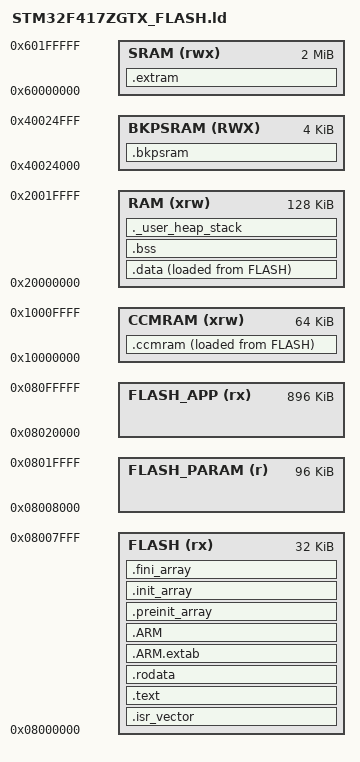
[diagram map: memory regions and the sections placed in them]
/*
******************************************************************************
**
** @file        : LinkerScript.ld
**
** @author      : Auto-generated by STM32CubeIDE
**
** @brief       : Linker script for STM32F417ZGTx Device from STM32F4 series
**                      1024KBytes FLASH
**                      64KBytes CCMRAM
**                      128KBytes RAM
**
**                Set heap size, stack size and stack location according
**                to application requirements.
**
**                Set memory bank area and size if external memory is used
**
**  Target      : STMicroelectronics STM32
**
**  Distribution: The file is distributed as is, without any warranty
**                of any kind.
**
******************************************************************************
** @attention
**
** Copyright (c) 2026 STMicroelectronics.
** All rights reserved.
**
** This software is licensed under terms that can be found in the LICENSE file
** in the root directory of this software component.
** If no LICENSE file comes with this software, it is provided AS-IS.
**
******************************************************************************
*/

/*
===================================================================================
                       STM32F4 CUSTOM MEMORY MAP ARCHITECTURE
===================================================================================
 [REGION]         [ADDRESS RANGE]         [SIZE]     [PURPOSE / TARGET ASSIGNMENT]
 ----------------------------------------------------------------------------------
 INTERNAL FLASH:
  Sector 0        0x0800 0000 - 0x0800 3FFF   16 KB    DFU Bootloader Vector/Init
  Sector 1        0x0800 4000 - 0x0800 7FFF   16 KB    DFU Bootloader Main Code (32KB)
  Sector 2        0x0800 8000 - 0x0800 BFFF   16 KB    Configuration Parameters A
  Sector 3        0x0800 C000 - 0x0800 FFFF   16 KB    Configuration Parameters B
  Sector 4        0x0801 0000 - 0x0801 FFFF   64 KB    Configuration Parameters C (96KB)
  Sectors 5-11    0x0802 0000 - 0x080F FFFF  896 KB    User Application Space (20KB+)

 EXTERNAL SYSTEM BUS:
  FSMC Bank 1     0x6000 0000 - 0x601F FFFF  2048 KB   External Parallel SRAM (2 MB)

===================================================================================
                       CRITICAL CONFIGURATION ATTENTION REMARKS
===================================================================================
 1. HARDWARE PROTECTION RULES (usbd_dfu_if.c):
    - Any incoming USB write/erase target address < 0x08020000 MUST be aborted 
      with USBD_FAIL to preserve the Bootloader (Sectors 0-1) and Parameters (Sectors 2-4).
    - Address targets between 0x60000000 and 0x601FFFFF must bypass standard internal
      flash procedures and route directly onto the parallel FSMC lines byte-by-byte.

 2. USER APPLICATION SETTINGS (Application Project Compiler Hooks):
    - Application Linker Script must set: FLASH (rx) ORIGIN = 0x08020000
    - Vector Table Offset (system_stm32f4xx.c) must read: VECT_TAB_OFFSET = 0x00020000U

 3. RUNTIME MEMORY MAPPING RULES:
    - External SRAM variables must utilize the (NOLOAD) linker section attribute to
      prevent the startup code from clearing it before MX_FSMC_Init() fires.
===================================================================================
*/

/* Entry Point */
ENTRY(Reset_Handler)

/* Highest address of the user mode stack */
_estack = ORIGIN(RAM) + LENGTH(RAM); /* end of "RAM" Ram type memory */

_Min_Heap_Size = 0x200; /* required amount of heap */
_Min_Stack_Size = 0x400; /* required amount of stack */

/* Memories definition */
MEMORY
{
  CCMRAM    (xrw)    : ORIGIN = 0x10000000,   LENGTH = 64K
  RAM    (xrw)    : ORIGIN = 0x20000000,   LENGTH = 128K
  BKPSRAM (RWX) : ORIGIN = 0x40024000, LENGTH = 4K
  SRAM (rwx)    : ORIGIN = 0x60000000, LENGTH =   2048k
  
  /* Primary active code execution space (Sectors 0-1) */
  FLASH    (rx)    : ORIGIN = 0x8000000,   LENGTH = 32K
  /* Parameter retention sector assignments (Sectors 2-4) */
  FLASH_PARAM  (r)   : ORIGIN = 0x08008000, LENGTH = 96K
  /* Main target runtime deployment space (Sectors 5-11) */
  FLASH_APP    (rx)  : ORIGIN = 0x08020000, LENGTH = 896K
}

/* Sections */
SECTIONS
{

  /* The startup code into "FLASH" Rom type memory */
  .isr_vector :
  {
    . = ALIGN(4);
    KEEP(*(.isr_vector)) /* Startup code */
    . = ALIGN(4);
  } >FLASH

  /* The program code and other data into "FLASH" Rom type memory */
  .text :
  {
    . = ALIGN(4);
    *(.text)           /* .text sections (code) */
    *(.text*)          /* .text* sections (code) */
    *(.glue_7)         /* glue arm to thumb code */
    *(.glue_7t)        /* glue thumb to arm code */
    *(.eh_frame)

    KEEP (*(.init))
    KEEP (*(.fini))

    . = ALIGN(4);
    _etext = .;        /* define a global symbols at end of code */
  } >FLASH

  /* Constant data into "FLASH" Rom type memory */
  .rodata :
  {
    . = ALIGN(4);
    *(.rodata)         /* .rodata sections (constants, strings, etc.) */
    *(.rodata*)        /* .rodata* sections (constants, strings, etc.) */
    . = ALIGN(4);
  } >FLASH

  .ARM.extab (READONLY) : /* The "READONLY" keyword is only supported in GCC11 and later, remove it if using GCC10 or earlier. */
  {
    . = ALIGN(4);
    *(.ARM.extab* .gnu.linkonce.armextab.*)
    . = ALIGN(4);
  } >FLASH

  .ARM (READONLY) : /* The "READONLY" keyword is only supported in GCC11 and later, remove it if using GCC10 or earlier. */
  {
    . = ALIGN(4);
    __exidx_start = .;
    *(.ARM.exidx*)
    __exidx_end = .;
    . = ALIGN(4);
  } >FLASH

  .preinit_array (READONLY) : /* The "READONLY" keyword is only supported in GCC11 and later, remove it if using GCC10 or earlier. */
  {
    . = ALIGN(4);
    PROVIDE_HIDDEN (__preinit_array_start = .);
    KEEP (*(.preinit_array*))
    PROVIDE_HIDDEN (__preinit_array_end = .);
    . = ALIGN(4);
  } >FLASH

  .init_array (READONLY) : /* The "READONLY" keyword is only supported in GCC11 and later, remove it if using GCC10 or earlier. */
  {
    . = ALIGN(4);
    PROVIDE_HIDDEN (__init_array_start = .);
    KEEP (*(SORT(.init_array.*)))
    KEEP (*(.init_array*))
    PROVIDE_HIDDEN (__init_array_end = .);
    . = ALIGN(4);
  } >FLASH

  .fini_array (READONLY) : /* The "READONLY" keyword is only supported in GCC11 and later, remove it if using GCC10 or earlier. */
  {
    . = ALIGN(4);
    PROVIDE_HIDDEN (__fini_array_start = .);
    KEEP (*(SORT(.fini_array.*)))
    KEEP (*(.fini_array*))
    PROVIDE_HIDDEN (__fini_array_end = .);
    . = ALIGN(4);
  } >FLASH

  /* Used by the startup to initialize data */
  _sidata = LOADADDR(.data);

  /* Initialized data sections into "RAM" Ram type memory */
  .data :
  {
    . = ALIGN(4);
    _sdata = .;        /* create a global symbol at data start */
    *(.data)           /* .data sections */
    *(.data*)          /* .data* sections */
    *(.RamFunc)        /* .RamFunc sections */
    *(.RamFunc*)       /* .RamFunc* sections */

    . = ALIGN(4);
    _edata = .;        /* define a global symbol at data end */

  } >RAM AT> FLASH

  _siccmram = LOADADDR(.ccmram);

  /* CCM-RAM section
  *
  * IMPORTANT NOTE!
  * If initialized variables will be placed in this section,
  * the startup code needs to be modified to copy the init-values.
  */
  .ccmram :
  {
    . = ALIGN(4);
    _sccmram = .;       /* create a global symbol at ccmram start */
    *(.ccmram)
    *(.ccmram*)

    . = ALIGN(4);
    _eccmram = .;       /* create a global symbol at ccmram end */
  } >CCMRAM AT> FLASH
  
  /* Add section for external RAM */
  .extram (NOLOAD) :
  {
  	. = ALIGN(4);
	_sextram = .;         /* define a global symbol at extram start */
	*(.extram)
	*(.extram*)    
	
	. = ALIGN(4);
	_eextram = .;         /* define a global symbol at extram end */	
  } >SRAM
  
  .bkpsram (NOLOAD) :
  {
	. = ALIGN(4);
	_sbkpsram = .;         /* define a global symbol at bckram start */
	*(.bkpsram);
	*(.bkpsram*);
	
	. = ALIGN(4);
	_ebkpsram = .;         /* define a global symbol at bckram end */	
  } > BKPSRAM

  /* Uninitialized data section into "RAM" Ram type memory */
  . = ALIGN(4);
  .bss :
  {
    /* This is used by the startup in order to initialize the .bss section */
    _sbss = .;         /* define a global symbol at bss start */
    __bss_start__ = _sbss;
    *(.bss)
    *(.bss*)
    *(COMMON)

    . = ALIGN(4);
    _ebss = .;         /* define a global symbol at bss end */
    __bss_end__ = _ebss;
  } >RAM

  /* User_heap_stack section, used to check that there is enough "RAM" Ram  type memory left */
  ._user_heap_stack :
  {
    . = ALIGN(8);
    PROVIDE ( end = . );
    PROVIDE ( _end = . );
    . = . + _Min_Heap_Size;
    . = . + _Min_Stack_Size;
    . = ALIGN(8);
  } >RAM

  /* Remove information from the compiler libraries */
  /DISCARD/ :
  {
    libc.a ( * )
    libm.a ( * )
    libgcc.a ( * )
  }

  .ARM.attributes 0 : { *(.ARM.attributes) }
  
  /* Export anchors for your firmware code to read boundaries */
  _flash_param_start = ORIGIN(FLASH_PARAM);
  _flash_param_end   = ORIGIN(FLASH_PARAM) + LENGTH(FLASH_PARAM);
  
  _flash_app_start   = ORIGIN(FLASH_APP);
  _flash_app_end     = ORIGIN(FLASH_APP) + LENGTH(FLASH_APP);
}
